# STM32F030xC register map
File version: 1.0
Registers are 32-bit, read-write, reset 0x0 unless marked. A register's access mark holds for its fields unless they carry their own. Offsets are from the block's base; [hi:lo] are bit positions; {n}, {i} and the like mark numbered series.

## SPI2 — Serial Peripheral Interface
Base 0x40003800
Same registers: SPI1 0x40013000
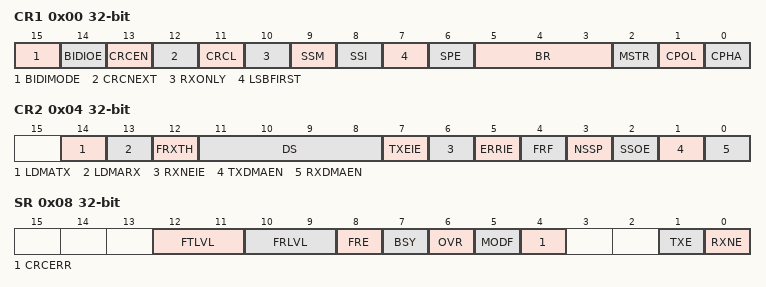
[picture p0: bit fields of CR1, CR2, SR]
0x00 CR1 — SPI Control register 1 (not used in I2S mode)
  [15] BIDIMODE — Bidirectional data mode enable
  [14] BIDIOE — Output enable in bidirectional mode
  [13] CRCEN — Hardware CRC calculation enable
  [12] CRCNEXT — Transmit CRC next
  [11] CRCL — CRC Length
    0=CRC_8BIT (8-bit CRC length); 1=CRC_16BIT (16-bit CRC length)
  [10] RXONLY — Receive only
  [9] SSM — Software slave management
  [8] SSI — Internal slave select
  [7] LSBFIRST — Frame Format
    1=LSB_FIRST (Data is transmitted/received with the LSB first); 0=MSB_FIRST (Data is transmitted/received with the MSB first)
  [6] SPE — SPI Enable
  [5:3] BR — BR[2:0] bits (Baud Rate Control)
    0=DIV2 (BaudRate control equal to fPCLK/2); 1=DIV4 (BaudRate control equal to fPCLK/4); 2=DIV8 (BaudRate control equal to fPCLK/8); 3=DIV16 (BaudRate control equal to fPCLK/16); 4=DIV32 (BaudRate control equal to fPCLK/32); 5=DIV64 (BaudRate control equal to fPCLK/64); 6=DIV128 (BaudRate control equal to fPCLK/128); 7=DIV256 (BaudRate control equal to fPCLK/256)
  [2] MSTR — Master Selection
  [1] CPOL — Clock Polarity
    0=LOW (Clock to 0 when idle); 1=HIGH (Clock to 1 when idle)
  [0] CPHA — Clock Phase
    0=PHASE_1EDGE (First clock transition is the first data capture edge); 1=PHASE_2EDGE (Second clock transition is the first data capture edge)
0x04 CR2 — SPI Control register 2
  [14] LDMATX — Last DMA transfer for transmission
  [13] LDMARX — Last DMA transfer for reception
  [12] FRXTH — FIFO reception Threshold
    0=HALF (RXNE event is generated if FIFO level is greater than or equal to 1/2 (16-bit)); 1=QUARTER (RXNE event is generated if FIFO level is greater than or equal to 1/4 (8-bit))
  [11:8] DS — DS[3:0] Data Size
    {v}=DATAWIDTH_{v+1}BIT (Data length for SPI transfer: {v+1} bits) (v=3..15)
  [7] TXEIE — Tx buffer Empty Interrupt Enable
  [6] RXNEIE — RX buffer Not Empty Interrupt Enable
  [5] ERRIE — Error Interrupt Enable
  [4] FRF — Frame Format Enable
    0=MOTOROLA (Motorola mode. Used as default value); 1=TI (TI mode)
  [3] NSSP — NSS pulse management Enable
  [2] SSOE — SS Output Enable
  [1] TXDMAEN — Tx Buffer DMA Enable
  [0] RXDMAEN — Rx Buffer DMA Enable
0x08 SR — SPI Status register
  [12:11] FTLVL — FIFO Transmission Level
    0=EMPTY (FIFO transmission empty); 1=QUARTER_FULL (FIFO transmission 1/4); 2=HALF_FULL (FIFO transmission 1/2); 3=FULL (FIFO transmission full)
  [10:9] FRLVL — FIFO Reception Level
    0=EMPTY (FIFO reception empty); 1=QUARTER_FULL (FIFO reception 1/4); 2=HALF_FULL (FIFO reception 1/2); 3=FULL (FIFO reception full)
  [8] FRE — TI frame format error
  [7] BSY — Busy flag
  [6] OVR — Overrun flag
  [5] MODF — Mode fault
  [4] CRCERR — CRC Error flag
  [1] TXE — Transmit buffer Empty
  [0] RXNE — Receive buffer Not Empty
0x0C DR — SPI data register
  [31:0] DR — Data Register
0x10 CRCPR — SPI CRC polynomial register (not used in I2S mode)
  [31:0] CRCPOLY — CRC polynomial register
0x14 RXCRCR — SPI Rx CRC register (not used in I2S mode)
  [31:0] RXCRC
0x18 TXCRCR — SPI Tx CRC register (not used in I2S mode)
  [31:0] TXCRC
0x1C I2SCFGR — SPI_I2S configuration register
  [11] I2SMOD — Keep for compatibility

## I2C2 — Inter-integrated Circuit Interface
Base 0x40005800
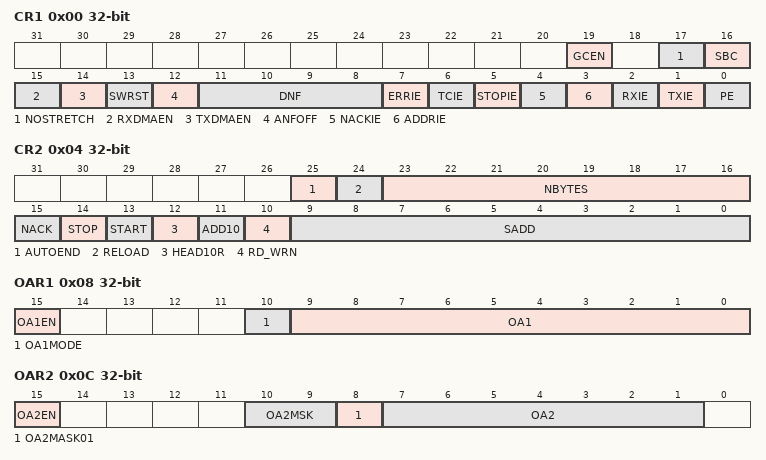
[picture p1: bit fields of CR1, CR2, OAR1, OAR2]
0x00 CR1 — I2C Control register 1
  [19] GCEN — General call enable
  [17] NOSTRETCH — Clock stretching disable
  [16] SBC — Slave byte control
  [15] RXDMAEN — DMA reception requests enable
  [14] TXDMAEN — DMA transmission requests enable
  [13] SWRST — Software reset
  [12] ANFOFF — Analog noise filter OFF
  [11:8] DNF — Digital noise filter
  [7] ERRIE — Errors interrupt enable
  [6] TCIE — Transfer complete interrupt enable
  [5] STOPIE — STOP detection interrupt enable
  [4] NACKIE — NACK received interrupt enable
  [3] ADDRIE — Address match interrupt enable
  [2] RXIE — RX interrupt enable
  [1] TXIE — TX interrupt enable
  [0] PE — Peripheral enable
0x04 CR2 — I2C Control register 2
  [25] AUTOEND — Automatic end mode (master mode)
  [24] RELOAD — NBYTES reload mode
  [23:16] NBYTES — Number of bytes
  [15] NACK — NACK generation (slave mode)
    0=ACK (ACK is sent after current received byte.); 1=NACK (NACK is sent after current received byte.)
  [14] STOP — STOP generation (master mode)
  [13] START — START generation
  [12] HEAD10R — 10-bit address header only read direction (master mode)
  [11] ADD10 — 10-bit addressing mode (master mode)
    0=MODE_7BIT (Master operates in 7-bit addressing mode.); 1=MODE_10BIT (Master operates in 10-bit addressing mode.)
  [10] RD_WRN — Transfer direction (master mode)
    0=WRITE (Master request a write transfer.); 1=READ (Master request a read transfer.)
  [9:0] SADD — Slave address (master mode)
0x08 OAR1 — I2C Own address 1 register
  [15] OA1EN — Own address 1 enable
  [10] OA1MODE — Own address 1 10-bit mode
  [9:0] OA1 — Interface own address 1
0x0C OAR2 — I2C Own address 2 register
  [15] OA2EN — Own address 2 enable
  [10:9] OA2MSK — Own address 2 masks
  [8] OA2MASK01 — OA2[1] is masked, Only OA2[7:2] are compared
  [7:1] OA2 — Interface own address 2
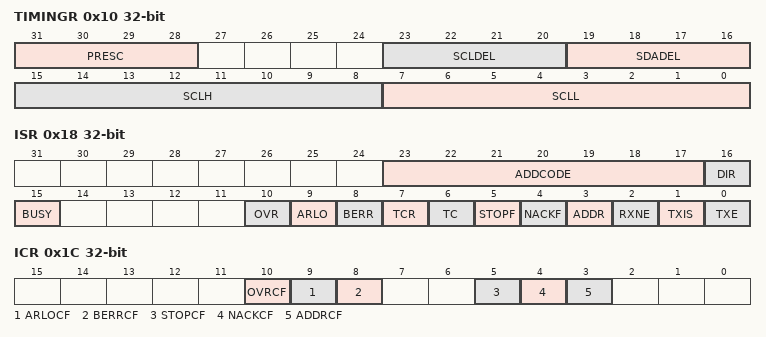
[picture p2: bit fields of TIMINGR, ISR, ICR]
0x10 TIMINGR — I2C Timing register
  [31:28] PRESC — Timings prescaler
  [23:20] SCLDEL — Data setup time
  [19:16] SDADEL — Data hold time
  [15:8] SCLH — SCL high period (master mode)
  [7:0] SCLL — SCL low period (master mode)
0x18 ISR — I2C Interrupt and status register
  [23:17] ADDCODE — Address match code (slave mode)
  [16] DIR — Transfer direction (slave mode)
    0=WRITE; 1=READ
  [15] BUSY — Bus busy
  [10] OVR — Overrun/Underrun
  [9] ARLO — Arbitration lost
  [8] BERR — Bus error
  [7] TCR — Transfer complete reload
  [6] TC — Transfer complete (master mode)
  [5] STOPF — STOP detection flag
  [4] NACKF — NACK received flag
  [3] ADDR — Address matched (slave mode)
  [2] RXNE — Receive data register not empty
  [1] TXIS — Transmit interrupt status
  [0] TXE — Transmit data register empty
0x1C ICR — I2C Interrupt clear register
  [10] OVRCF — Overrun/Underrun clear flag
  [9] ARLOCF — Arbitration lost clear flag
  [8] BERRCF — Bus error clear flag
  [5] STOPCF — STOP detection clear flag
  [4] NACKCF — NACK clear flag
  [3] ADDRCF — Address matched clear flag
0x24 RXDR — I2C Receive data register
  [7:0] RXDATA — 8-bit receive data
0x28 TXDR — I2C Transmit data register
  [7:0] TXDATA — 8-bit transmit data
